# R7FA6T2BD register map
Vendor: Renesas Electronics Corporation; Series: RA6; File version: 1.40.00
CPU: CM33 r0p4, little endian, MPU, FPU, VTOR, 4 interrupt priority bits, 96 interrupts
Registers are 32-bit, read-write, reset 0x0 unless marked. A register's access mark holds for its fields unless they carry their own. Offsets are from the block's base; [hi:lo] are bit positions; lines under a group give offsets from that group; {n}, {i} and the like mark numbered series; 'fields as' and 'values as' point back to an identical list; <NAME> marks a mode.

## GPT320 (part 2 of 2) — General PWM 32-bit Timer 0
Base 0x40169000
Same registers: GPT321 0x40169100, GPT322 0x40169200, GPT323 0x40169300
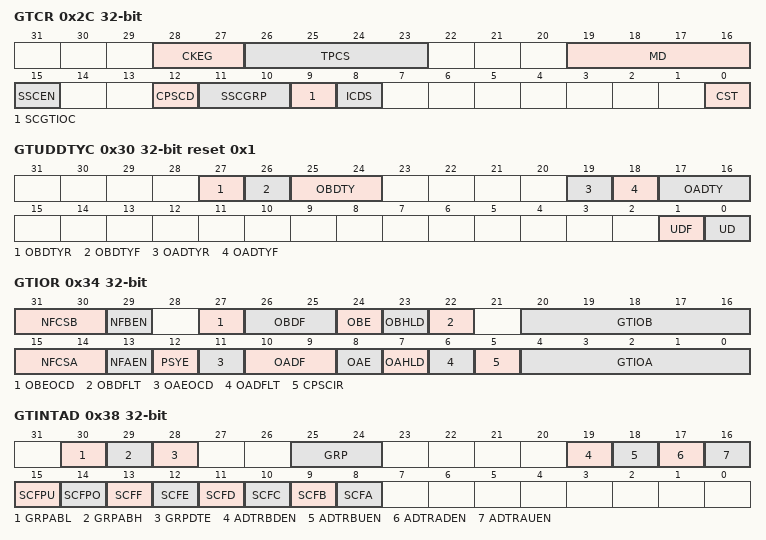
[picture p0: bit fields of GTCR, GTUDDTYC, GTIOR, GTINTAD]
0x2C GTCR — General PWM Timer Control Register
  [28:27] CKEG — Clock Edge Select
    0=Select rising edge of GTETRG for clock count; 1=Select falling edge of GTETRG for clock count; other=Others (Select both edge of GTETRG for clock count)
  [26:23] TPCS — Timer Prescaler Select
    0=GTCLK/1; 1=GTCLK/2; 2=GTCLK/4; 3=GTCLK/8; 4=GTCLK/16; 5=GTCLK/32; 6=GTCLK/64; 7=GTCLK/128; 8=GTCLK/256; 9=GTCLK/512; 10=GTCLK/1024; 11=Setting prohibited; 12=GTETRGA (Via the POEG); 13=GTETRGB (Via the POEG); 14=GTETRGC (Via the POEG); 15=GTETRGD (Via the POEG)POEG接続数に応じた、GTETRGA-D表示制御必要。
  [19:16] MD — Mode Select
    0=Saw-wave PWM mode 1(single buffer or double buffer possible); 1=Saw-wave one-shot pulse mode (fixed buffer operation); 2=Saw-wave PWM mode 2(single buffer or double buffer possible); 3=Setting prohibited; 4=Triangle-wave PWM mode 1 (32-bit transfer at trough) (single buffer or double buffer possible); 5=Triangle-wave PWM mode 2 (32-bit transfer at crest and trough) (single buffer or double buffer possible); 6=Triangle-wave PWM mode 3 (64-bit transfer at trough) (fixed buffer operation); {v}=Setting prohibited (v=7..11); 12=Complementary PWM mode 1(transfer at crest); 13=Complementary PWM mode 2(transfer at trough); 14=Complementary PWM mode 3(transfer at crest and trough); 15=Complementary PWM mode 4(immediate transfer)
  [15] SSCEN — Synchronous Set/Clear Enable
    0=Disable Synchronous set/clear of the GTCNT counter; 1=Enable Synchronous set/clear of the GTCNT counter
  [12] CPSCD — Complementary PWM Mode Synchronous Clear Disable
    0=Enable synchronous counter clear by other channel other than the section of trough in complementary PWM mode; 1=Disable synchronous counter clear by other channel other than the section of trough in complementary PWM mode
  [11:10] SSCGRP — Synchronous Set/Clear Group Select
    0=Select synchronous set/clear group A; 1=Select synchronous set/clear group B; 2=Select synchronous set/clear group C; 3=Select synchronous set/clear group D
  [9] SCGTIOC — GTIOC input Source Synchronous Clear Enable
    0=Disables to use the counter clear by GTIOC input as the clear factor for other channels; 1=Enables to use the counter clear by GTIOC input as the clear factor for other channels
  [8] ICDS — Input Capture Operation Select During Count Stop
    0=Input capture is operated during count stop; 1=Input capture is not operated during count stop
  [0] CST — Count Start
    0=Count operation is stopped; 1=Count operation is performed
0x30 GTUDDTYC reset 0x1 — General PWM Timer Count Direction and Duty Setting Register
  [27] OBDTYR — GTIOCnB Output Value Selecting after Releasing 0%/100% Duty Setting
    0=The function selected by the GTIOB[3:2] bits is applied to the output value when the duty cycle is set after release from the 0 or 100% duty-cycle setting; 1=The function selected by the GTIOB[3:2] bits is applied to the compare match output value which is masked after release from the 0 or 100% duty-cycle setting
  [26] OBDTYF — Forcible GTIOCnB Output Duty Setting
    0=Not forcibly set; 1=Forcibly set
  [25:24] OBDTY — GTIOCnB Output Duty Setting
    0=GTIOCnB pin duty depends on the compare match; 1=GTIOCnB pin duty depends on the compare match; 2=GTIOCnB pin duty 0%; 3=GTIOCnB pin duty 100%
  [19] OADTYR — GTIOCnA Output Value Selecting after Releasing 0%/100% Duty Setting
    0=The function selected by the GTIOA[3:2] bits is applied to the output value when the duty cycle is set after release from the 0 or 100% duty-cycle setting; 1=The function selected by the GTIOA[3:2] bits is applied to the compare match output value which is masked after release from the 0 or 100% duty-cycle setting
  [18] OADTYF — Forcible GTIOCnA Output Duty Setting
    0=Not forcibly set; 1=Forcibly set
  [17:16] OADTY — GTIOCnA Output Duty Setting
    0=GTIOCnA pin duty depends on the compare match; 1=GTIOCnA pin duty depends on the compare match; 2=GTIOCnA pin duty 0%; 3=GTIOCnA pin duty 100%
  [1] UDF — Forcible Count Direction Setting
    0=Not forcibly set; 1=Forcibly set
  [0] UD — Count Direction Setting
    0=GTCNT counts down; 1=GTCNT counts up
0x34 GTIOR — General PWM Timer I/O Control Register
  [31:30] NFCSB — Noise Filter B Sampling Clock Select
    0=GTCLK/1; 1=GTCLK/4; 2=GTCLK/16; 3=GTCLK/64
  [29] NFBEN — Noise Filter B Enable
    0=The noise filter for the GTIOCnB pin is disabled; 1=The noise filter for the GTIOCnB pin is enabled
  [27] OBEOCD — GTCCRB Compare Match Cycle End Output Invalidate
    0=When Saw-wave PWM mode 1, validate GTIOB[3:2] setting When Saw-wave PWM mode 2, validate GTIOA[3:2] setting; 1=When Saw-wave PWM mode 1, invalidate GTIOB[3:2] setting (GTIOCnB pin output is retained) When Saw-wave PWM mode 2, invalidate GTIOA[3:2] setting (GTIOCnA pin output is retained)
  [26:25] OBDF — GTIOCnB Pin Disable Value Setting
    0=None of the below options are specified; 1=GTIOCnB pin is set to Hi-Z in response to controlling the output negation; 2=GTIOCnB pin is set to 0 in response to controlling the output negation; 3=GTIOCnB pin is set to 1 in response to controlling the output negation
  [24] OBE — GTIOCnB Pin Output Enable
    0=Output is disabled; 1=Output is enabled
  [23] OBHLD — GTIOCnB Pin Output Setting at the Start/Stop Count
    0=The GTIOCnB pin output level at the start/stop of counting depends on the register setting; 1=The GTIOCnB pin output level is retained at the start/stop of counting
  [22] OBDFLT — GTIOCnB Pin Output Value Setting at the Count Stop
    0=The GTIOCnB pin outputs low when counting stops; 1=The GTIOCnB pin outputs high when counting stops
  [20:16] GTIOB — GTIOCnB Pin Function Select
  [15:14] NFCSA — Noise Filter A Sampling Clock Select
    0=GTCLK/1; 1=GTCLK/4; 2=GTCLK/16; 3=GTCLK/64
  [13] NFAEN — Noise Filter A Enable
    0=The noise filter for the GTIOCnA pin is disabled; 1=The noise filter for the GTIOCnA pin is enabled
  [12] PSYE — PWM Synchronous output Enable
    0=Disable GTCPPOm pin output; 1=Enable GTCPPOm pin output
  [11] OAEOCD — GTCCRA Compare Match Cycle End Output Invalidate
    0=Validate GTIOA[3:2] setting; 1=Invalidate GTIOA[3:2] setting (GTIOCnA pin output is retained)
  [10:9] OADF — GTIOCnA Pin Disable Value Setting
    0=None of the below options are specified; 1=GTIOCnA pin is set to Hi-Z in response to controlling the output negation; 2=GTIOCnA pin is set to 0 in response to controlling the output negation; 3=GTIOCnA pin is set to 1 in response to controlling the output negation
  [8] OAE — GTIOCnA Pin Output Enable
    0=Output is disabled; 1=Output is enabled
  [7] OAHLD — GTIOCnA Pin Output Setting at the Start/Stop Count
    0=The GTIOCnA pin output level at the start or stop of counting depends on the register setting; 1=The GTIOCnA pin output level is retained at the start or stop of counting
  [6] OADFLT — GTIOCnA Pin Output Value Setting at the Count Stop
    0=The GTIOCnA pin outputs low when counting stops; 1=The GTIOCnA pin outputs high when counting stops
  [5] CPSCIR — Complementary PWM Mode Initial Output at Synchronous Clear Disable
    0=Output the initial value set by the GTIOR.GTIOA and GTIOB bits when synchronous clear occurs in Trough section of complementary PWM mode; 1=Disable output the initial value
  [4:0] GTIOA — GTIOCnA Pin Function Select
0x38 GTINTAD — General PWM Timer Interrupt Output Setting Register
  [30] GRPABL — Same Time Output Level Low Disable Request Enable
    0=Same time output level low disable request disabled; 1=Same time output level low disable request enabled
  [29] GRPABH — Same Time Output Level High Disable Request Enable
    0=Same time output level high disable request disabled; 1=Same time output level high disable request enabled
  [28] GRPDTE — Dead Time Error Output Disable Request Enable
    0=Dead time error output disable request is disabled; 1=Dead time error output disable request is enabled
  [25:24] GRP — Output Disable Source Select
    0=Group A output disable source is selected Group B output disable source is selected Group C output disable source is selected Group D output disable source is selected
  [19] ADTRBDEN — GTADTRB Register Compare Match (Down-Counting) A/D Conversion Start Request Enable
    0=A/D conversion start request is disabled; 1=A/D conversion start request is enabled
  [18] ADTRBUEN — GTADTRB Register Compare Match (Up-Counting) A/D Conversion Start Request Enable
    values as ADTRBDEN
  [17] ADTRADEN — GTADTRA Register Compare Match (Down-Counting) A/D Conversion Start Request Enable
    values as ADTRBDEN
  [16] ADTRAUEN — GTADTRA Register Compare Match (Up-Counting) A/D Conversion Start Request Enable
    values as ADTRBDEN
  [15] SCFPU — Underflow Source Synchronous Clear Enable
    0=Disable use of underflow as a clear factor for other channels; 1=Enable use of underflow as a clear factor for other channels
  [14] SCFPO — Overflow Source Synchronous Clear Enable
    0=Disable use of overflow as a clear factor for other channels; 1=Enable use of overflow as a clear factor for other channels
  [13] SCFF — GTCCRF Register Compare Match Source Synchronous Clear Enable
    0=Disable use of GTCCRF register compare match as a clear factor for other channels; 1=Enable use of GTCCRF register compare match as a clear factor for other channels
  [12] SCFE — GTCCRE Register Compare Match Source Synchronous Clear Enable
    0=Disable use of GTCCRE register compare match as a clear factor for other channels; 1=Enable use of GTCCRE register compare match as a clear factor for other channels
  [11] SCFD — GTCCRD Register Compare Match Source Synchronous Clear Enable
    0=Disable use of GTCCRD register compare match as a clear factor for other channels; 1=Enable use of GTCCRD register compare match as a clear factor for other channels
  [10] SCFC — GTCCRC Register Compare Match Source Synchronous Clear Enable
    0=Disable use of GTCCRC register compare match as a clear factor for other channels; 1=Enable use of GTCCRC register compare match as a clear factor for other channels
  [9] SCFB — GTCCRB Register Compare Match/Input Capture Source Synchronous Clear Enable
    0=Disable use of GTCCRB register compare match/input capture as a clear factor for other channels; 1=Enable use of GTCCRB register compare match/input capture as a clear factor for other channels
  [8] SCFA — GTCCRA Register Compare Match/Input Capture Source Synchronous Clear Enable
    0=Disable use of GTCCRA register compare match/input capture as a clear factor for other channels; 1=Enable use of GTCCRA register compare match/input capture as a clear factor for other channels
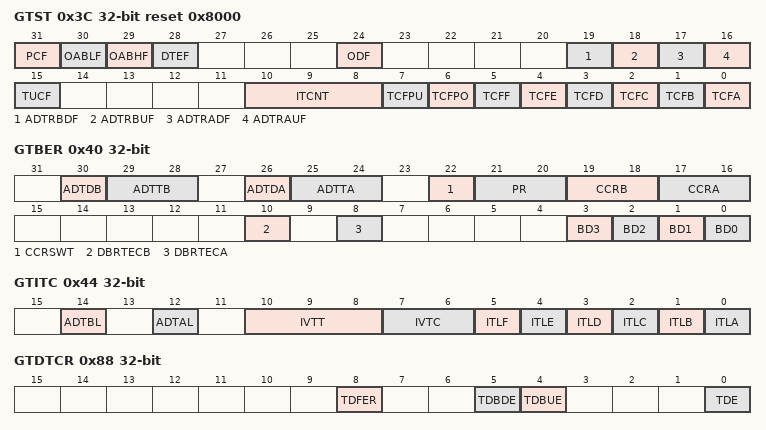
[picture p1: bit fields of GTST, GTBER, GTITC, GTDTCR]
0x3C GTST reset 0x8000 — General PWM Timer Status Register
  [31] PCF — Period Count Function Finish Flag
    0=No period count function finish has occurred; 1=A period count function finish has occurred
  [30] OABLF ro — Same Time Output Level Low Flag
    0=No simultaneous generation of 0 both for the GTIOCA and GTIOCB pins has occurred; 1=A simultaneous generation of 0 both for the GTIOCA and GTIOCB pins has occurred
  [29] OABHF ro — Same Time Output Level High Flag
    0=No simultaneous generation of 1 both for the GTIOCA and GTIOCB pins has occurred; 1=A simultaneous generation of 1 both for the GTIOCA and GTIOCB pins has occurred
  [28] DTEF ro — Dead Time Error Flag
    0=No dead time error has occurred; 1=A dead time error has occurred
  [24] ODF ro — Output Disable Flag
    0=No output disable request is generated; 1=An output disable request is generated
  [19] ADTRBDF — GTADTRB Register Compare Match (Down-Counting) A/D Conversion Start Request Flag
    0=No GTADTRB register compare match has occurred in down-counting; 1=A GTADTRB register compare match has occurred in down-counting
  [18] ADTRBUF — GTADTRB Register Compare Match (Up-Counting) A/D Conversion Start Request Flag
    0=No GTADTRB register compare match has occurred in up-counting; 1=A GTADTRB register compare match has occurred in up-counting
  [17] ADTRADF — GTADTRA Register Compare Match (Down-Counting) A/D Conversion Start Request Flag
    0=No GTADTRA register compare match has occurred in down-counting; 1=A GTADTRA register compare match has occurred in down-counting
  [16] ADTRAUF — GTADTRA Register Compare Match (Up-Counting) A/D Conversion Start Request Flag
    0=No GTADTRA register compare match has occurred in up-counting; 1=A GTADTRA register compare match has occurred in up-counting
  [15] TUCF ro — Count Direction Flag
    0=GTCNT counter counts downward; 1=GTCNT counter counts upward
  [10:8] ITCNT ro — GPTn_OVF/GPTn_UDF Interrupt Skipping Count Counter
  [7] TCFPU — Underflow Flag
    0=No underflow (trough) occurred; 1=An underflow (trough) occurred
  [6] TCFPO — Overflow Flag
    0=No overflow (crest) occurred; 1=An overflow (crest) occurred
  [5] TCFF — Input Compare Match Flag F
    0=No compare match of GTCCRF is generated; 1=A compare match of GTCCRF is generated
  [4] TCFE — Input Compare Match Flag E
    0=No compare match of GTCCRE is generated; 1=A compare match of GTCCRE is generated
  [3] TCFD — Input Compare Match Flag D
    0=No compare match of GTCCRD is generated; 1=A compare match of GTCCRD is generated
  [2] TCFC — Input Compare Match Flag C
    0=No compare match of GTCCRC is generated; 1=A compare match of GTCCRC is generated
  [1] TCFB — Input Capture/Compare Match Flag B
    0=No input capture/compare match of GTCCRB is generated; 1=An input capture/compare match of GTCCRB is generated
  [0] TCFA — Input Capture/Compare Match Flag A
    0=No input capture/compare match of GTCCRA is generated; 1=An input capture/compare match of GTCCRA is generated
0x40 GTBER — General PWM Timer Buffer Enable Register
  [30] ADTDB — GTADTRB Register Double Buffer Operation
    0=Single buffer operation (GTADTBRB --> GTADTRB); 1=Double buffer operation (GTADTDBRB --> GTADTBRB --> GTADTRB)
  [29:28] ADTTB — GTADTRB Register Buffer Transfer Timing Select
    0=In triangle wave or complementary PWM mode, no transfer. In saw-wave mode, no transfer.; 1=In triangle wave or complementary PWM mode, transfer at crest. In saw-wave mode, transfer at underflow (in down-counting), overflow (in up-counting), or counter clearing.; 2=In triangle wave or complementary PWM mode, transfer at trough. In saw-wave mode, transfer at underflow (in down-counting), overflow (in up-counting), or counter clearing.; 3=In triangle wave or complementary PWM mode, transfer at both crest and trough. In saw-wave mode, transfer at underflow (in down-counting), overflow (in up-counting), or counter clearing.
  [26] ADTDA — GTADTRA Register Double Buffer Operation
    0=Single buffer operation (GTADTBRA --> GTADTRA); 1=Double buffer operation (GTADTDBRA --> GTADTBRA --> GTADTRA)
  [25:24] ADTTA — GTADTRA Register Buffer Transfer Timing Select
    values as ADTTB
  [22] CCRSWT wo — GTCCRA and GTCCRB Forcible Buffer Operation
  [21:20] PR — GTPR Buffer Operation
    0=No buffer operation; 1=Single buffer operation (GTPBR --> GTPR); other=Others (Double buffer operation (GTPDBR --> GTPBR --> GTPR))
  [19:18] CCRB — GTCCRB Buffer Operation
    0=No buffer operation; 1=Single buffer operation (GTCCRB <----> GTCCRE); other=Others (Double buffer operation (GTCCRB <----> GTCCRE <----> GTCCRF))
  [17:16] CCRA — GTCCRA Buffer Operation
    0=No buffer operation; 1=Single buffer operation (GTCCRA <---->GTCCRC); other=Others (Double buffer operation (GTCCRA <----> GTCCRC <----> GTCCRD))
  [10] DBRTECB — GTCCRB Register Double Buffer Repeat Operation Enable
    0=GTCCRB register double buffer repeat operation is disabled; 1=GTCCRB register double buffer repeat operation is enabled
  [8] DBRTECA — GTCCRA Register Double Buffer Repeat Operation Enable
    0=GTCCRA register double buffer repeat operation is disabled; 1=GTCCRA register double buffer repeat operation is enabled
  [3] BD3 — GTDVU/GTDVD Registers Buffer Operation Disable
    0=Buffer operation is enabled; 1=Buffer operation is disabled
  [2] BD2 — GTADTRA/GTADTRB Registers Buffer Operation Disable
    values as BD3
  [1] BD1 — GTPR Buffer Operation Disable
    values as BD3
  [0] BD0 — GTCCR Buffer Operation Disable
    values as BD3
0x44 GTITC — General PWM Timer Interrupt and A/D Conversion Start Request Skipping Setting Register
  [14] ADTBL — GTADTRB Register A/D Conversion Start Request Link
    0=Not linked with GPTn_OVF/GPTn_UDF interrupt skipping function; 1=Linked with GPTn_OVF/GPTn_UDF interrupt skipping function
  [12] ADTAL — GTADTRA Register A/D Conversion Start Request Link
    values as ADTBL
  [10:8] IVTT — GPTn_OVF/GPTn_UDF Interrupt Skipping Count Select
    0=Skipping is not performed; {v}=Skipping count of {v} (v=1..7)
  [7:6] IVTC — GPTn_OVF/GPTn_UDF Interrupt Skipping Function Select
    0=Skipping is not performed; 1=Both overflow and underflow for saw waves and crest for triangle waves and complementary PWM mode are counted and skipped; 2=Both overflow and underflow for saw waves and trough for triangle waves and complementary PWM mode are counted and skipped; 3=Both overflow and underflow for saw waves and both crest and trough for triangle waves and complementary PWM mode are counted and skipped
  [5] ITLF — GTCCRF Register Compare Match Interrupt Link
    values as ADTBL
  [4] ITLE — GTCCRE Register Compare Match Interrupt Link
    values as ADTBL
  [3] ITLD — GTCCRD Register Compare Match Interrupt Link
    values as ADTBL
  [2] ITLC — GTCCRC Register Compare Match Interrupt Link
    values as ADTBL
  [1] ITLB — GTCCRB Register Compare Match/Input Capture Interrupt Link
    values as ADTBL
  [0] ITLA — GTCCRA Register Compare Match/Input Capture Interrupt Link
    values as ADTBL
0x48 GTCNT — General PWM Timer Counter
0x4C GTCCRA reset 0xFFFFFFFF — General PWM Timer Compare Capture Register A
0x50 GTCCRB reset 0xFFFFFFFF — General PWM Timer Compare Capture Register B
0x54 GTCCRC reset 0xFFFFFFFF — General PWM Timer Compare Capture Register C
0x58 GTCCRE reset 0xFFFFFFFF — General PWM Timer Compare Capture Register E
0x5C GTCCRD reset 0xFFFFFFFF — General PWM Timer Compare Capture Register D
0x60 GTCCRF reset 0xFFFFFFFF — General PWM Timer Compare Capture Register F
0x64 GTPR reset 0xFFFFFFFF — General PWM Timer Cycle Setting Register
0x68 GTPBR reset 0xFFFFFFFF — General PWM Timer Cycle Setting Buffer Register
0x6C GTPDBR reset 0xFFFFFFFF — General PWM Timer Cycle Setting Double-Buffer Register
0x70 GTADTRA reset 0xFFFFFFFF — A/D Conversion Start Request Timing Register A
0x74 GTADTBRA reset 0xFFFFFFFF — A/D Conversion Start Request Timing Buffer Register A
0x78 GTADTDBRA reset 0xFFFFFFFF — A/D Conversion Start Request Timing Double-Buffer Register A
0x7C GTADTRB reset 0xFFFFFFFF — A/D Conversion Start Request Timing Register B
0x80 GTADTBRB reset 0xFFFFFFFF — A/D Conversion Start Request Timing Buffer Register B
0x84 GTADTDBRB reset 0xFFFFFFFF — A/D Conversion Start Request Timing Double-Buffer Register B
0x88 GTDTCR — General PWM Timer Dead Time Control Register
  [8] TDFER — GTDVD Register Setting
    0=GTDVU and GTDVD registers are set separately; 1=The value written to GTDVU register is automatically set to GTDVD register
  [5] TDBDE — GTDVD Register Buffer Operation Enable
    0=GTDVD register buffer operation is disabled; 1=GTDVD register buffer operation is enabled
  [4] TDBUE — GTDVU Register Buffer Operation Enable
    0=GTDVU register buffer operation is disabled; 1=GTDVU register buffer operation is enabled
  [0] TDE — Negative-Phase Waveform Setting
    0=GTCCRB is set without using GTDVU and GTDVD; 1=GTDVU and GTDVD are used to set the compare match value for negative-phase waveform with dead time automatically in GTCCRB
0x8C GTDVU reset 0xFFFFFFFF — General PWM Timer Dead Time Value Register U
0x90 GTDVD reset 0xFFFFFFFF — General PWM Timer Dead Time Value Register D
0x94 GTDBU reset 0xFFFFFFFF — General PWM Timer Dead Time Buffer Register U
0x98 GTDBD reset 0xFFFFFFFF — General PWM Timer Dead Time Buffer Register D
0x9C GTSOS ro — General PWM Timer Output Protection Function Status Register
  [1:0] SOS — Output Protection Function Status
    0=Normal operation; 1=Protected state (GTCCRA = 0 is set during transfer at trough or crest); 2=Protected state (GTCCRA ≥ GTPR is set during transfer at trough); 3=Protected state (GTCCRA ≥ GTPR is set during transfer at crest)
0xA0 GTSOTR — General PWM Timer Output Protection Function Temporary Release Register
  [0] SOTR — Output Protection Function Temporary Release
    0=Protected state is not released; 1=Protected state is released
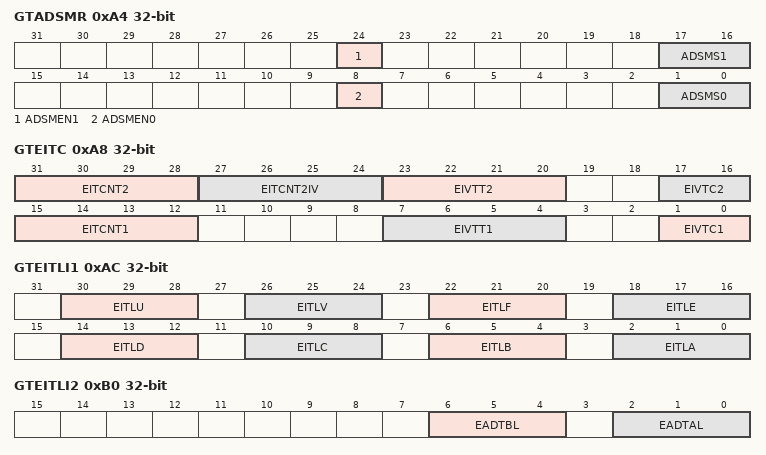
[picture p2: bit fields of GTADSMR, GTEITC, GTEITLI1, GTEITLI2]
0xA4 GTADSMR — General PWM Timer A/D Conversion Start Request Signal Monitoring Register
  [24] ADSMEN1 — A/D Conversion Start Request Signal Monitor 1 Output Enabling
    0=Output of A/D conversion start request signal monitor 1 is disabled; 1=Output of A/D conversion start request signal monitor 1 is enabled
  [17:16] ADSMS1 — A/D Conversion Start Request Signal Monitor 1 Selection
    0=A/D conversion start request signal generated by the GTADTRA register during up-counting; 1=A/D conversion start request signal generated by the GTADTRA register during down-counting; 2=A/D conversion start request signal generated by the GTADTRB register during up-counting; 3=A/D conversion start request signal generated by the GTADTRB register during down-counting
  [8] ADSMEN0 — A/D Conversion Start Request Signal Monitor 0 Output Enabling
    0=Output of A/D conversion start request signal monitor 0 is disabled; 1=Output of A/D conversion start request signal monitor 0 is enabled
  [1:0] ADSMS0 — A/D Conversion Start Request Signal Monitor 0 Selection
    values as ADSMS1
0xA8 GTEITC — General PWM Timer Extended Interrupt Skipping Counter Control Register
  [31:28] EITCNT2 ro — Extended Interrupt Skipping Counter 2
  [27:24] EITCNT2IV — Extended Interrupt Skipping Counter 2 Initial Value
  [23:20] EIVTT2 — Extended Interrupt Skipping 2 Skipping Count Setting
  [17:16] EIVTC2 — Extended Interrupt Skipping Counter 2 Count Source select
    0=Not counted (not skipped); 1=Counting both at overflow or underflow in saw-wave mode, and counting crests in triangle-wave mode or complementary PWM mode; 2=Counting both at overflow or underflow in saw-wave mode, and counting troughs in triangle-wave mode or complementary PWM mode; 3=Counting both at overflow or underflow in saw-wave mode, and counting both crests and troughs in triangle-wave mode or complementary PWM mode
  [15:12] EITCNT1 ro — Extended Interrupt Skipping Counter 1
  [7:4] EIVTT1 — Extended Interrupt Skipping 1 Skipping Count Setting
  [1:0] EIVTC1 — Extended Interrupt Skipping Counter 1 Count Source Select
    values as EIVTC2
0xAC GTEITLI1 — General PWM Timer Extended Interrupt Skipping Setting Register 1
  [30:28] EITLU — Underflow Interrupt Extended Skipping Function Select
  [26:24] EITLV — Overflow Interrupt Extended Skipping Function Select
  [22:20] EITLF — GTCCRF Register Compare Match Interrupt Extended Skipping Function Select
  [18:16] EITLE — GTCCRE Register Compare Match Interrupt Extended Skipping Function Select
  [14:12] EITLD — GTCCRD Register Compare Match Interrupt Extended Skipping Function Select
  [10:8] EITLC — GTCCRC Register Compare Match Interrupt Extended Skipping Function Select
  [6:4] EITLB — GTCCRB Register Compare Match/Input Capture Interrupt Extended Skipping Function Select
  [2:0] EITLA — GTCCRA Register Compare Match/Input Capture Interrupt Extended Skipping Function Select
0xB0 GTEITLI2 — General PWM Timer Extended Interrupt Skipping Setting Register 2
  [6:4] EADTBL — GTADTRB Register A/D Conversion Start Request Extended Skipping Function Select
  [2:0] EADTAL — GTADTRA Register A/D Conversion Start Request Extended Skipping Function Select
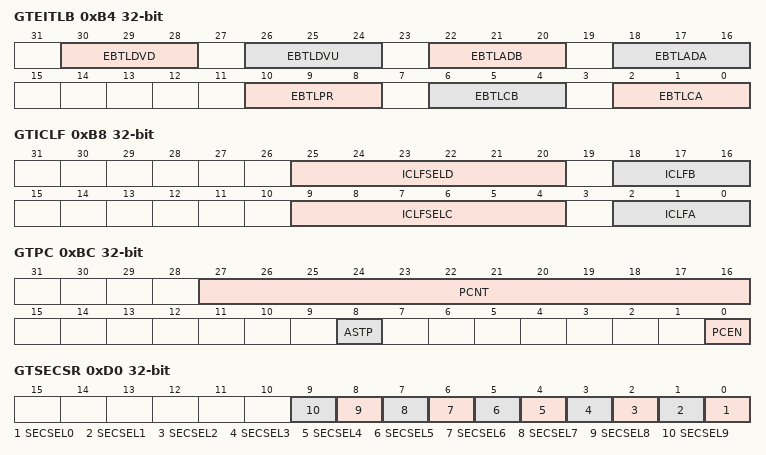
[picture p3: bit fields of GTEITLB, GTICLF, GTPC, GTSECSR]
0xB4 GTEITLB — General PWM Timer Extended Buffer Transfer Skipping Setting Register
  [30:28] EBTLDVD — GTDVD Register Buffer Transfer Extended Skipping Function Select
  [26:24] EBTLDVU — GTDVU Register Buffer Transfer Extended Skipping Function Select
  [22:20] EBTLADB — GTADTRB Register Buffer Transfer Extended Skipping Function Select
  [18:16] EBTLADA — GTADTRA Register Buffer Transfer Extended Skipping Function Select
  [10:8] EBTLPR — GTPR Register Buffer Transfer Extended Skipping Function Select
  [6:4] EBTLCB — GTCCRB Register Buffer Transfer Extended Skipping Function Select
  [2:0] EBTLCA — GTCCRA Register Buffer Transfer Extended Skipping Function Select
0xB8 GTICLF — General PWM Timer Inter Channel Logical Operation Function Setting Register
  [25:20] ICLFSELD — Inter Channel Signal D Select
  [18:16] ICLFB — GTIOCnB Output Logical Operation Function Select
    0=B (no delay); 1=NOT B (no delay); 2=D (1GTCLK delay); 3=NOT D (1GTCLK delay); 4=B AND D (1GTCLK delay); 5=B OR D (1GTCLK delay); 6=B EXOR D (1GTCLK delay); 7=B NOR D (1GTCLK delay)
  [9:4] ICLFSELC — Inter Channel Signal C Select
  [2:0] ICLFA — GTIOCnA Output Logical Operation Function Select
    0=A (no delay); 1=NOT A (no delay); 2=C (1GTCLK delay); 3=NOT C (1GTCLK delay); 4=A AND C (1GTCLK delay); 5=A OR C (1GTCLK delay); 6=A EXOR C (1GTCLK delay); 7=A NOR C (1GTCLK delay)
0xBC GTPC — General PWM Timer Period Count Register
  [27:16] PCNT — Period Counter
  [8] ASTP — Automatic Stop Function Enable
    0=Automatic stop function is disabled; 1=Automatic stop function is enabled
  [0] PCEN — Period Count Function Enable
    0=Period count function is disabled; 1=Period count function is enabled
0xD0 GTSECSR — General PWM Timer Operation Enable Bit Simultaneous Control Channel Select Register
  [all] fields
    0=Disable simultaneous control; 1=Enable simultaneous control
  [n] SECSEL{n} (n=0..9) — Channel {n} Operation Enable Bit Simultaneous Control Channel Select
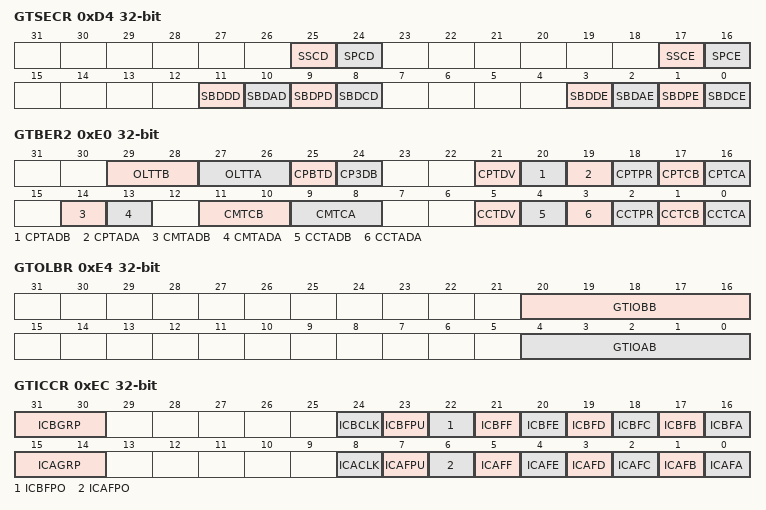
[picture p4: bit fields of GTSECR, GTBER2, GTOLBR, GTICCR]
0xD4 GTSECR — General PWM Timer Operation Enable Bit Simultaneous Control Register
  [25] SSCD — Synchronous Set/Clear Simultaneous Disable
    0=Disable simultaneous disabling synchronous set/clear; 1=Disable synchronous set/clear simultaneously
  [24] SPCD — Period Count Function Simultaneous Disable
    0=Disable simultaneous disabling period count function; 1=Disable period count function simultaneously
  [17] SSCE — Synchronous Set/Clear Simultaneous Enable
    0=Disable simultaneous enabling synchronous set/clear; 1=Enable synchronous set/clear simultaneously
  [16] SPCE — Period Count Function Simultaneous Enable
    0=Disable simultaneous enabling period count function; 1=Enable period count function simultaneously
  [11] SBDDD — GTDV Register Buffer Operation Simultaneous Disable
    0=Disable simultaneous disabling GTDV buffer operations; 1=Disable GTDV register buffer operations simultaneously
  [10] SBDAD — GTADTR Register Buffer Operation Simultaneous Disable
    0=Disable simultaneous disabling GTADTR buffer operations; 1=Disable GTADTR register buffer operations simultaneously
  [9] SBDPD — GTPR Register Buffer Operation Simultaneous Disable
    0=Disable simultaneous disabling GTPR buffer operations; 1=Disable GTPR register buffer operations simultaneously
  [8] SBDCD — GTCCR Register Buffer Operation Simultaneous Disable
    0=Disable simultaneous disabling GTCCR buffer operations; 1=Disable GTCCR register buffer operations simultaneously
  [3] SBDDE — GTDV Register Buffer Operation Simultaneous Enable
    0=Disable simultaneous enabling GTDV buffer operations; 1=Enable GTDV register buffer operations simultaneously
  [2] SBDAE — GTADTR Register Buffer Operation Simultaneous Enable
    0=Disable simultaneous enabling GTADTR buffer operations; 1=Enable GTADTR register buffer operations simultaneously
  [1] SBDPE — GTPR Register Buffer Operation Simultaneous Enable
    0=Disable simultaneous enabling GTPR buffer operations; 1=Enable GTPR register buffer operations simultaneously
  [0] SBDCE — GTCCR Register Buffer Operation Simultaneous Enable
    0=Disable simultaneous enabling GTCCR buffer operations; 1=Enable GTCCR register buffer operations simultaneously
0xE0 GTBER2 — General PWM Timer Buffer Enable Register 2
  [29:28] OLTTB — GTIOCnB Output Level Buffer Transfer Timing Select
    0=No transfer; 1=Triangle waves, complementary PWM mode: Transfer at crest Saw waves: Transfer at the end of period; 2=Triangle waves, complementary PWM mode: Transfer at trough Saw waves: Transfer by compare match of GTCCRB register; 3=Triangle waves, complementary PWM mode: Transfer at both crest and trough Saw waves: Setting prohibited
  [27:26] OLTTA — GTIOCnA Output Level Buffer Transfer Timing Select
    0=No transfer; 1=Triangle waves, complementary PWM mode: Transfer at crest Saw waves: Transfer at the end of period; 2=Triangle waves, complementary PWM mode: Transfer at trough Saw waves: Transfer by compare match of GTCCRA register; 3=Triangle waves, complementary PWM mode: Transfer at both crest and trough Saw waves: Setting prohibited
  [25] CPBTD — Complementary PWM mode Buffer Transfer Disable
    0=Enable buffer transfer from temporary register to GTCCRC and GTPBR register; 1=Disable buffer transfer from temporary register to GTCCRC and GTPBR register
  [24] CP3DB — Complementary PWM mode 3,4 Double Buffer select
    0=Disable double buffer function in complementary PWM mode 3, 4; 1=Enable double buffer function in complementary PWM mode 3, 4
  [21] CPTDV — Overflow/Underflow Source GTDVU/GTDVD Register Buffer Transfer Disable
    0=Enable GTDVU/GTDVD register buffer transfer by overflow/underflow; 1=Disable GTDVU/GTDVD register buffer transfer by overflow/underflow
  [20] CPTADB — Overflow/Underflow Source GTADTRB Register Buffer Transfer Disable
    0=Enable GTADTRB register buffer transfer by overflow/underflow; 1=Disable GTADTRB register buffer transfer by overflow/underflow
  [19] CPTADA — Overflow/Underflow Source GTADTRA Register Buffer Transfer Disable
    0=Enable GTADTRA register buffer transfer by overflow/underflow; 1=Disable GTADTRA register buffer transfer by overflow/underflow
  [18] CPTPR — Overflow/Underflow Source GTPR Register Buffer Transfer Disable
    0=Enable GTPR register buffer transfer by overflow/underflow; 1=Disable GTPR register buffer transfer by overflow/underflow
  [17] CPTCB — Overflow/Underflow Source GTCCRB Register Buffer Transfer Disable
    0=Enable GTCCRB register buffer transfer by overflow/underflow; 1=Disable GTCCRB register buffer transfer by overflow/underflow
  [16] CPTCA — Overflow/Underflow Source GTCCRA Register Buffer Transfer Disable
    0=Enable GTCCRA register buffer transfer by overflow/underflow; 1=Disable GTCCRA register buffer transfer by overflow/underflow
  [14] CMTADB — Compare Match Source GTADTRB Register Buffer Transfer Enable
    0=Disable GTADTRB register buffer transfer by compare match of GTADTRB register; 1=Enable GTADTRB register buffer transfer by compare match of GTADTRB register
  [13] CMTADA — Compare Match Source GTADTRA Register Buffer Transfer Enable
    0=Disable GTADTRA register buffer transfer by compare match of GTADTRA register; 1=Enable GTADTRA register buffer transfer by compare match of GTADTRA register
  [11:10] CMTCB — Compare Match Source GTCCRB Register Buffer Transfer Enable
    0=Disable GTCCRB register Buffer Transfer by compare match of GTCCRA register and GTCCRB register; 1=Enable GTCCRB register Buffer Transfer by compare match of GTCCRA register; 2=Enable GTCCRB register Buffer Transfer by compare match of GTCCRB register; 3=Enable GTCCRB register Buffer Transfer by compare match of GTCCRA register and GTCCRB register
  [9:8] CMTCA — Compare Match Source GTCCRA Register Buffer Transfer Enable
    0=Disable GTCCRA register Buffer Transfer by compare match of GTCCRA register and GTCCRB register; 1=Enable GTCCRA register Buffer Transfer by compare match of GTCCRA register; 2=Enable GTCCRA register Buffer Transfer by compare match of GTCCRB register; 3=Enable GTCCRA register Buffer Transfer by compare match of GTCCRA register and GTCCRB register
  [5] CCTDV — Counter Clear Source GTDVU/GTDVD Register Buffer Transfer Disable
    0=Enable GTDVU/GTDVD register buffer transfer by counter clear; 1=Disable GTDVU/GTDVD register buffer transfer by counter clear
  [4] CCTADB — Counter Clear Source GTADTRB Register Buffer Transfer Disable
    0=Enable GTADTRB register buffer transfer by counter clear; 1=Disable GTADTRB register buffer transfer by counter clear
  [3] CCTADA — Counter Clear Source GTADTRA Register Buffer Transfer Disable
    0=Enable GTADTRA register buffer transfer by counter clear; 1=Disable GTADTRA register buffer transfer by counter clear
  [2] CCTPR — Counter Clear Source GTPR Register Buffer Transfer Disable
    0=Enable GTPR register buffer transfer by counter clear; 1=Disable GTPR register buffer transfer by counter clear
  [1] CCTCB — Counter Clear Source GTCCRB Register Buffer Transfer Disable
    0=Enable GTCCRB register buffer transfer by counter clear; 1=Disable GTCCRB register buffer transfer by counter clear
  [0] CCTCA — Counter Clear Source GTCCRA Register Buffer Transfer Disable
    0=Enable GTCCRA register buffer transfer by counter clear; 1=Disable GTCCRA register buffer transfer by counter clear
0xE4 GTOLBR — General PWM Timer Output Level Buffer Register
  [20:16] GTIOBB — GTIOB buffer bits
  [4:0] GTIOAB — GTIOA buffer bits
0xEC GTICCR — General PWM Timer Inter Channel Cooperation Input Capture Control Register
  [31:30] ICBGRP — GTCCRB Input Capture Group Select
    0=Select group A; 1=Select group B; 2=Select group C; 3=Select group D
  [24] ICBCLK — Forwarding Count Clock to Other Channel GTCCRB Input Capture Source Enable
    0=Disable forwarding count clock to GTCCRB input capture source of other channels; 1=Enable forwarding count clock to GTCCRB input capture source of other channels
  [23] ICBFPU — Forwarding Underflow to Other Channel GTCCRB Input Capture Source Enable
    0=Disable forwarding underflow in saw-waves or the trough in triangle-waves or complementary PWM mode to GTCCRB input capture source of other channels; 1=Enable forwarding underflow in saw-waves or the trough in triangle-waves or complementary PWM mode to GTCCRB input capture source of other channels
  [22] ICBFPO — Forwarding Overflow to Other Channel GTCCRB Input Capture Source Enable
    0=Disable forwarding overflow in saw-waves or the crest in triangle-waves or complementary PWM mode to GTCCRB input capture source of other channels; 1=Enable forwarding overflow in saw-waves or the crest in triangle-waves or complementary PWM mode to GTCCRB input capture source of other channels
  [21] ICBFF — Forwarding GTCCRF register Compare Match to Other Channel GTCCRB Input Capture Source Enable
    0=Disable forwarding GTCCRF register compare match to GTCCRB input capture source of other channels; 1=Enable forwarding GTCCRF register compare match to GTCCRB input capture source of other channels
  [20] ICBFE — Forwarding GTCCRE register Compare Match to Other Channel GTCCRB Input Capture Source Enable
    0=Disable forwarding GTCCRE register compare match to GTCCRB input capture source of other channels; 1=Enable forwarding GTCCRE register compare match to GTCCRB input capture source of other channels
  [19] ICBFD — Forwarding GTCCRD register Compare Match to Other Channel GTCCRB Input Capture Source Enable
    0=Disable forwarding GTCCRD register compare match to GTCCRB input capture source of other channels; 1=Enable forwarding GTCCRD register compare match to GTCCRB input capture source of other channels
  [18] ICBFC — Forwarding GTCCRC register Compare Match to Other Channel GTCCRB Input Source Capture Enable
    values as ICBFD
  [17] ICBFB — Forwarding GTCCRB register Compare Match/Input Capture to Other Channel GTCCRB Input Capture Source Enable
    0=Disable forwarding GTCCRB register compare match/input capture to GTCCRB input capture source of other channels; 1=Enable forwarding GTCCRB register compare match/input capture to GTCCRB input capture source of other channels
  [16] ICBFA — Forwarding GTCCRA register Compare Match/Input Capture to Other Channel GTCCRB Input Capture Source Enable
    0=Disable forwarding GTCCRA register compare match/input capture to GTCCRB input capture source of other channels; 1=Enable forwarding GTCCRA register compare match/input capture to GTCCRB input capture source of other channels
  [15:14] ICAGRP — GTCCRA Input Capture Group Select
    values as ICBGRP
  [8] ICACLK — Forwarding Count Clock to Other Channel GTCCRA Input Capture Source Enable
    0=Disable forwarding count clock to GTCCRA input capture source of other channels; 1=Enable forwarding count clock to GTCCRA input capture source of other channels
  [7] ICAFPU — Forwarding Underflow to Other Channel GTCCRA Input Capture Source Enable
    0=Disable forwarding underflow in saw-waves or the trough in triangle-waves or complementary PWM mode to GTCCRA input capture source of other channels; 1=Enable forwarding underflow in saw-waves or the trough in triangle-waves or complementary PWM mode to GTCCRA input capture source of other channels
  [6] ICAFPO — Forwarding Overflow to Other Channel GTCCRA Input Capture Source Enable
    0=Disable forwarding overflow in saw-waves or the crest in triangle-waves or complementary PWM mode to GTCCRA input capture source of other channels; 1=Enable forwarding overflow in saw-waves or the crest in triangle-waves or complementary PWM mode to GTCCRA input capture source of other channels
  [5] ICAFF — Forwarding GTCCRF register Compare Match to Other Channel GTCCRA Input Capture Source Enable
    0=Disable forwarding GTCCRF register compare match to GTCCRA input capture source of other channels; 1=Enable forwarding GTCCRF register compare match to GTCCRA input capture source of other channels
  [4] ICAFE — Forwarding GTCCRE register Compare Match to Other Channel GTCCRA Input Capture Source Enable
    0=Disable forwarding GTCCRE register compare match to GTCCRA input capture source of other channels; 1=Enable forwarding GTCCRE register compare match to GTCCRA input capture source of other channels
  [3] ICAFD — Forwarding GTCCRD register Compare Match to Other Channel GTCCRA Input Capture Source Enable
    0=Disable forwarding GTCCRD register compare match to GTCCRA input capture source of other channels; 1=Enable forwarding GTCCRD register compare match to GTCCRA input capture source of other channels
  [2] ICAFC — Forwarding GTCCRC register Compare Match to Other Channel GTCCRA Input Source Capture Enable
    0=Disable forwarding GTCCRC register compare match to GTCCRA input capture source of other channels; 1=Enable forwarding GTCCRC register compare match to GTCCRA input capture source of other channels
  [1] ICAFB — Forwarding GTCCRB register Compare Match/Input Capture to Other Channel GTCCRA Input Capture Source Enable
    0=Disable forwarding GTCCRB register compare match/input capture to GTCCRA input capture source of other channels; 1=Enable forwarding GTCCRB register compare match/input capture to GTCCRA input capture source of other channels
  [0] ICAFA — Forwarding GTCCRA register Compare Match/Input Capture to Other Channel GTCCRA Input Capture Source Enable
    0=Disable forwarding GTCCRA register compare match/input capture to GTCCRA input capture source of other channels; 1=Enable forwarding GTCCRA register compare match/input capture to GTCCRA input capture source of other channels

## GPT324 (part 2 of 2) — General PWM 32-bit Timer 4
Base 0x40169400
Same registers: GPT325 0x40169500, GPT326 0x40169600, GPT327 0x40169700, GPT328 0x40169800, GPT329 0x40169900
Registers as GPT320, without GTPC; these are added or differ:
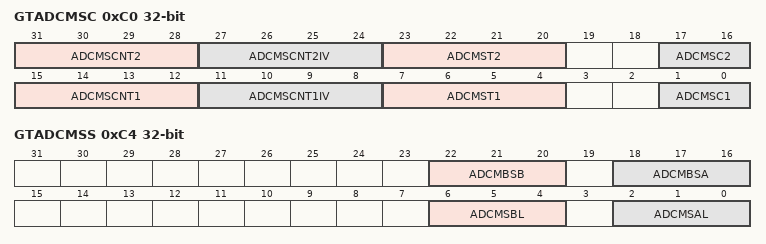
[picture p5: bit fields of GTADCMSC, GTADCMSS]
0xC0 GTADCMSC — General PWM Timer A/D Conversion Start Request Compare Match Skipping Control Register
  [31:28] ADCMSCNT2 ro — A/D Conversion Start Request Compare Match Skipping Counter 2
  [27:24] ADCMSCNT2IV — A/D Conversion Start Request Compare Match Skipping Counter 2 Initial Value
  [23:20] ADCMST2 — A/D Conversion Start Request Compare Match Skipping 2 Skipping Count Setting
  [17:16] ADCMSC2 — A/D Conversion Start Request Compare Match Skipping Counter 2 Count Source Select
    0=Not counted (not skipped); 1=Counting GTADTRA register compare match; 2=Counting GTADTRB register compare match; 3=Counting both GTADTRA register compare match and GTADTRB register compare match
  [15:12] ADCMSCNT1 ro — A/D Conversion Start Request Compare Match Skipping Counter 1
  [11:8] ADCMSCNT1IV — A/D Conversion Start Request Compare Match Skipping Counter 1 Initial Value
  [7:4] ADCMST1 — A/D Conversion Start Request Compare Match Skipping 1 Skipping Count Setting
  [1:0] ADCMSC1 — A/D Conversion Start Request Compare Match Skipping Counter 1 Count Source Select
    values as ADCMSC2
0xC4 GTADCMSS — General PWM Timer A/D Conversion Start Request Compare Match Skipping Setting Register
  [22:20] ADCMBSB — GTADTRB Register Buffer Transfer by A/D Conversion Start Request Compare Match Skipping Function Select
  [18:16] ADCMBSA — GTADTRA Register Buffer Transfer by A/D Conversion Start Request Compare Match Skipping Function Select
  [6:4] ADCMSBL — GTADTRB Register A/D Conversion Start Request Compare Match Skipping Function Select
  [2:0] ADCMSAL — GTADTRA Register A/D Conversion Start Request Compare Match Skipping Function Select
